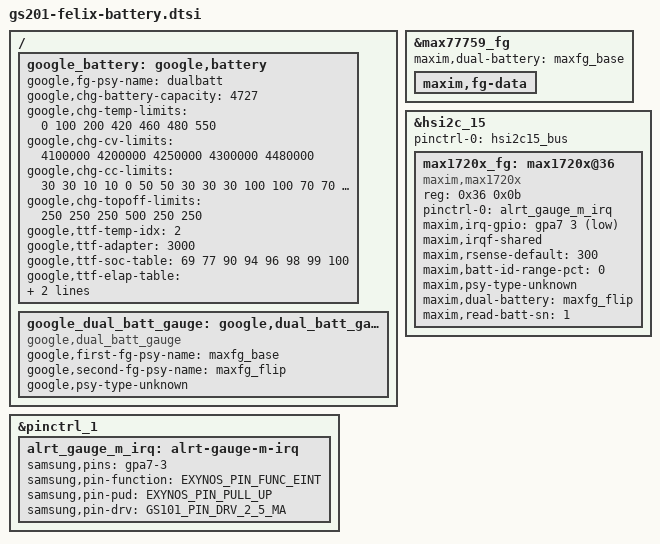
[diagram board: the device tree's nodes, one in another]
// SPDX-License-Identifier: GPL-2.0-only
/*
 * Battery device tree entries specific to felix
 *
 * Copyright 2022 Google,LLC
 *
 */

&max77759_fg {
	/delete-property/ maxim,force-batt-id;
	maxim,dual-battery = "maxfg_base";

//	maxim,filtercfg-temp = <100>;
//	maxim,filtercfg-temp-hysteresis = <30>;
//	maxim,filtercfg-default = /bits/ 16 <0xc613>;
//	maxim,filtercfg-adjust = /bits/ 16 <0xc617>;

	maxim,fg-data {
		#include "gs201-felix-battery-data.dtsi"
	};
};

/ {
	fragment@battery {
		target-path = "/";
		__overlay__ {

			google_battery: google,battery {
				google,fg-psy-name = "dualbatt";
				google,chg-battery-capacity = <4727>;

				/* charge table */
				google,chg-temp-limits = <0 100 200 420 460 480 550>;
				google,chg-cv-limits = <4100000 4200000 4250000 4300000 4480000>;
				google,chg-cc-limits = <
					 30  30  10  10   0
					 50  50  30  30  30
					100 100  70  70  50
					 80  80  50  50  50
					 50  50  50   0   0
					 30   0   0   0   0
				>;
				google,chg-topoff-limits = <250 250 250 500 250 250>;

				google,ttf-temp-idx= <2>;
				google,ttf-adapter = <3000>;
				google,ttf-soc-table =  <69 77 90 94  96  98  99  100>;
				google,ttf-elap-table = <41 62 78 115 170 230 308 152>;
				google,ttf-tier-table = <0 61 77>;
			};

			google_dual_batt_gauge: google,dual_batt_gauge {
				status = "okay";
				compatible = "google,dual_batt_gauge";
				google,first-fg-psy-name = "maxfg_base";
				google,second-fg-psy-name = "maxfg_flip";
				google,psy-type-unknown;
			};
		};
	};
};

&pinctrl_1 {
/* [MAX17201 : INTB] > ALRT_GAUGE_M > [XEINT_11] */
	alrt_gauge_m_irq: alrt-gauge-m-irq {
		samsung,pins = "gpa7-3"; /* XEINT_11 */
		samsung,pin-function = <EXYNOS_PIN_FUNC_EINT>;
		samsung,pin-pud = <EXYNOS_PIN_PULL_UP>;
		samsung,pin-drv = <GS101_PIN_DRV_2_5_MA>;
	};
};

&hsi2c_15 {
	#address-cells = <1>;
	#size-cells = <0>;
	status = "okay";

	pinctrl-names = "default";
	pinctrl-0 = <&hsi2c15_bus>;

	max1720x_fg: max1720x@36 {
		status = "okay";
		compatible = "maxim,max1720x";
		reg-names = "m5db", "nvram";
		reg = <0x36 0x0b>;

		pinctrl-names = "default";
		pinctrl-0 = <&alrt_gauge_m_irq>;
		maxim,irq-gpio = <&gpa7 3 GPIO_ACTIVE_LOW>;
		maxim,irqf-shared;

		maxim,rsense-default = <300>;

		/* no needed for EEPROM */
		maxim,batt-id-range-pct = <0>;
		maxim,psy-type-unknown;

		maxim,dual-battery = "maxfg_flip";
		maxim,read-batt-sn = <1>;
	};
};
